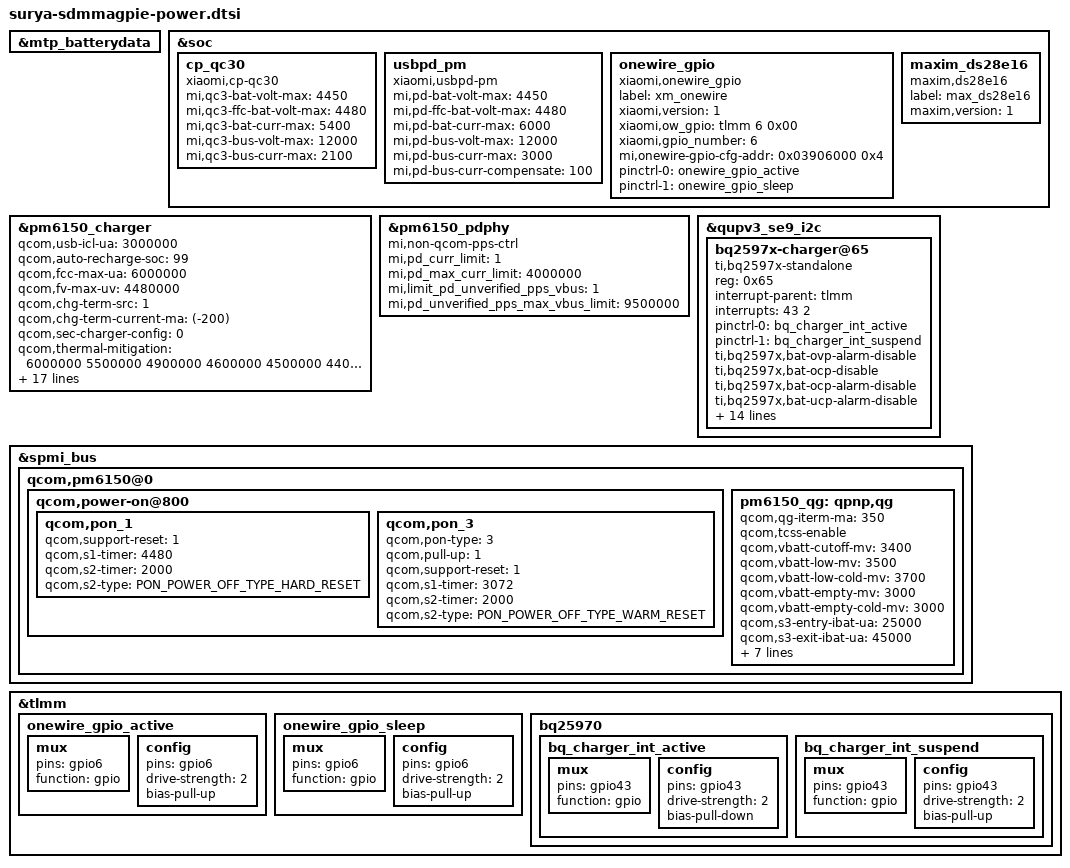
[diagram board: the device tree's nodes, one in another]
#include <dt-bindings/input/qcom,qpnp-power-on.h>

&mtp_batterydata {
	#include "battery/batterydata-M703-PM7150B-ATL-5160mah.dtsi"
	#include "battery/batterydata-M703-ATL-6000mah.dtsi"
};

&soc {
        cp_qc30 {
                compatible = "xiaomi,cp-qc30";
                status = "ok";
                mi,qc3-bat-volt-max = <4450>;
                mi,qc3-ffc-bat-volt-max = <4480>;
                mi,qc3-bat-curr-max = <5400>;
                mi,qc3-bus-volt-max = <12000>;
                mi,qc3-bus-curr-max = <2100>;
        };

	usbpd_pm {
		compatible = "xiaomi,usbpd-pm";
		status = "ok";
		mi,pd-bat-volt-max = <4450>;
		mi,pd-ffc-bat-volt-max = <4480>;
		mi,pd-bat-curr-max = <6000>;
		mi,pd-bus-volt-max = <12000>;
		mi,pd-bus-curr-max = <3000>;
		mi,pd-bus-curr-compensate = <100>;
	};

	onewire_gpio: onewire_gpio {
		compatible = "xiaomi,onewire_gpio";
		label = "xm_onewire";
		xiaomi,version = <1>;
		xiaomi,ow_gpio = <&tlmm 6 0x00>;
		xiaomi,gpio_number = <6>;
		mi,onewire-gpio-cfg-addr = <0x03906000 0x4>;
		pinctrl-names = "onewire_active", "onewire_sleep";
		pinctrl-0 = <&onewire_gpio_active>;
		pinctrl-1 = <&onewire_gpio_sleep>;
		status = "ok";
	};

	maxim_ds28e16: maxim_ds28e16 {
		compatible = "maxim,ds28e16";
		label = "max_ds28e16";
		maxim,version = <1>;
		status = "ok";
	};
};

&pm6150_qg {
	qcom,qg-iterm-ma = <350>;
	qcom,tcss-enable;
	qcom,vbatt-cutoff-mv = <3400>;
	qcom,vbatt-low-mv = <3500>;
	qcom,vbatt-low-cold-mv = <3700>;
	qcom,vbatt-empty-mv = <3000>;
	qcom,vbatt-empty-cold-mv = <3000>;
	qcom,s3-entry-ibat-ua = <25000>;
	qcom,s3-exit-ibat-ua = <45000>;
	qcom,s3-entry-fifo-length = <2>;
	qcom,qg-vadc = <&pm6150_vadc>;
	qcom,qg-ext-sns;
	mi,software-optimize-ffc-qg-iterm;
	qcom,soc_decimal_rate = <
		0  32
		10 30
		20 28
		30 28
		40 28
		50 28
		60 28
		70 28
		80 28
		90 26
		95 10
		99 5>;
	qcom,qg-fast-chg-config;
};

&pm6150_charger {
	/delete-property/ qcom,step-charging-enable;
	/delete-property/ qcom,fcc-stepping-enable;

	qcom,usb-icl-ua = <3000000>;
	qcom,auto-recharge-soc = <99>;
	qcom,fcc-max-ua = <6000000>;
	qcom,fv-max-uv = <4480000>;
	qcom,chg-term-src = <1>;
	qcom,chg-term-current-ma = <(-200)>;

	qcom,sec-charger-config = <0>;
	qcom,thermal-mitigation = <6000000 5500000 4900000 4600000 4500000 4400000 4200000
				   3800000 3800000 3600000 3400000 3200000 3000000 2200000
				   800000 700000>;

	qcom,fcc-step-delay-ms = <100>;
	qcom,fcc-step-size-ua = <100000>;
	qcom,disable-sw-thermal-regulation;
	qcom,disable-fcc-restriction;
	qcom,smb-internal-pull-kohm = <0>;
	qcom,usbpd-phandle = <&pm6150_pdphy>;
	mi,support-ffc;
	mi,six-pin-step-chg-params = <4250000 6000000
					4450000 5400000
					4480000 4000000>;
	mi,six-pin-step-chg-params_2 = <4250000 6000000
					4450000 5400000
					4480000 4680000>;
	mi,six-pin-step-chg;
	mi,use-bq-pump;
	qcom,distinguish-qc-class-ab;
	qcom,disable-suspend-on-collapse;
	mi,swithc-sel-gpio = <&tlmm 94 0>;
	qcom,lpd-disable;
};

&pm6150_pdphy {
	mi,non-qcom-pps-ctrl;
	mi,pd_curr_limit = <1>;
	mi,pd_max_curr_limit = <4000000>;
	mi,limit_pd_unverified_pps_vbus = <1>;
	mi,pd_unverified_pps_max_vbus_limit = <9500000>;
};

&qupv3_se9_i2c {
	bq2597x-charger@65 {
		compatible = "ti,bq2597x-standalone";
		reg = <0x65>;
		interrupt-parent = <&tlmm>;
		interrupts = <43 2>;
		pinctrl-names = "bq_charger_active", "bq_charger_suspend";
		pinctrl-0 = <&bq_charger_int_active>;
		pinctrl-1 = <&bq_charger_int_suspend>;

		ti,bq2597x,bat-ovp-alarm-disable;
		ti,bq2597x,bat-ocp-disable;
		ti,bq2597x,bat-ocp-alarm-disable;
		ti,bq2597x,bat-ucp-alarm-disable;
		ti,bq2597x,bat-ucp-disable;

		ti,bq2597x,bat-therm-disable;
		ti,bq2597x,bus-therm-disable;
		ti,bq2597x,die-therm-disable;

		ti,bq2597x,bat-ovp-threshold = <4550>;
		ti,bq2597x,bat-ovp-alarm-threshold = <4450>;

		ti,bq2597x,bus-ovp-threshold = <12000>;
		ti,bq2597x,bus-ovp-alarm-threshold = <11000>;

		ti,bq2597x,bus-ocp-threshold = <3500>;
		ti,bq2597x,bus-ocp-alarm-threshold = <3300>;

		ti,bq2597x,bat-therm-threshold = <0x15>;/*4.1%*/
		ti,bq2597x,bus-therm-threshold = <0x15>;/*4.1%*/
		ti,bq2597x,die-therm-threshold = <145>;
		ti,bq2597x,ac-ovp-threshold = <14>;
	};
};

&spmi_bus {
	qcom,pm6150@0 {
		qcom,power-on@800 {
			qcom,pon_1 {
				qcom,support-reset = <1>;
				qcom,s1-timer = <4480>;
				qcom,s2-timer = <2000>;
				qcom,s2-type = <PON_POWER_OFF_TYPE_HARD_RESET>;
			};

			qcom,pon_3 {
				qcom,pon-type = <3>;
				qcom,pull-up = <1>;
				qcom,support-reset = <1>;
				qcom,s1-timer = <3072>;
				qcom,s2-timer = <2000>;
				qcom,s2-type = <PON_POWER_OFF_TYPE_WARM_RESET>;
			};
		};
		pm6150_qg: qpnp,qg {
			/delete-property/ qcom,vbatt-cutoff-mv;
			/delete-property/ qcom,vbatt-low-mv;
			/delete-property/ qcom,vbatt-low-cold-mv;
			/delete-property/ qcom,vbatt-empty-mv;
			/delete-property/ qcom,vbatt-empty-cold-mv;
			/delete-property/ qcom,s3-entry-fifo-length;
		};
	};
};

&tlmm {
	onewire_gpio_active: onewire_gpio_active {
		mux {
			pins = "gpio6";
			function = "gpio";
		};

		config {
			pins = "gpio6";
			drive-strength = <2>;
			bias-pull-up;
		};
	};

	onewire_gpio_sleep: onewire_gpio_sleep {
		mux {
			pins = "gpio6";
			function = "gpio";
		};

		config {
			pins = "gpio6";
			drive-strength = <2>;
			bias-pull-up;
		};
	};

	bq25970 {
		bq_charger_int_active: bq_charger_int_active{
			mux {
				pins = "gpio43";
				function = "gpio";
			};
			config {
				pins = "gpio43";
				drive-strength = <2>;
			        bias-pull-down;
			};
		};
		bq_charger_int_suspend: bq_charger_int_suspend {
			mux {
				pins = "gpio43";
				function = "gpio";
			};
			config {
				pins = "gpio43";
				drive-strength = <2>;
				bias-pull-up;
			};
		};
	};
};
